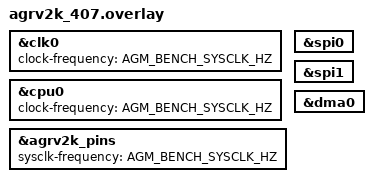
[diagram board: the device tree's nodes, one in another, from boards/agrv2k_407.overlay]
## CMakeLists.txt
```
# SPDX-License-Identifier: Apache-2.0
cmake_minimum_required(VERSION 3.20.0)
find_package(Zephyr REQUIRED HINTS $ENV{ZEPHYR_BASE})
project(fcb_reload)
target_sources(app PRIVATE src/main.c src/spi_id.c)
```

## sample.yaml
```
# SPDX-License-Identifier: Apache-2.0
sample:
  name: fcb_reload
  description: |
    Probe which bitstream is live after a FLASH-side reload: print the FCB
    STAT and a SPI0 RDID so the dev board can show that the fabric content
    follows FLASH while the firmware stays byte-identical. Reload =
    flash_logic.sh + reboot; there is no runtime hot-swap, because on
    AgRV2K the CPU's clock tree comes out of the fabric (see README.md).
    Bench-verified: pending (2026-09-14 board recovery still needed).
tests:
  sample.fcb_reload.agm_agrv2k_407:
    build_only: true
    platform_allow:
      - agrv2k_407
    integration_platforms:
      - agrv2k_407
    tags:
      - ci_build
      - hal_ag32
```

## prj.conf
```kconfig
# SPDX-License-Identifier: Apache-2.0
CONFIG_SERIAL=y
CONFIG_UART_CONSOLE=y
CONFIG_PRINTK=y
CONFIG_STDOUT_CONSOLE=y
CONFIG_XIP=y

# The probe reads the SPI NOR's RDID to tell which bitstream is live, so
# this is the same SPI/DMA set as spi_flash_id. No CONFIG_REBOOT: the
# sample never reboots itself — reloading means flash_logic.sh + reboot.
CONFIG_SPI=y
CONFIG_DMA=y
```

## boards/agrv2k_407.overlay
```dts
/* SPDX-License-Identifier: Apache-2.0 */
/*
 * fcb_reload — 100 MHz SYSCLK overlay.
 *
 * The SPI bitstreams at $HOME/spi_full_bitstream/ and
 * $HOME/spi_full_bitstream_without_flash/ are 100 MHz bitstreams
 * (vendor VE declares SYSCLK 100 / BUSCLK 100 / HSECLK 8). The default
 * agrv2k_407 dts assumes the 200 MHz vendor example_board.bin — running
 * fcb_reload against a 100 MHz bitstream at the default 200 MHz means
 * UART 115200 baud is wrong and the kernel tick drifts.
 *
 * Per the port record (peripherals) (clock tree note): cpu0 ::
 * clock-frequency must stay a literal — sys_clock ticks are computed
 * from it as an integer. &sys clock-frequency follows the same path
 * via DT_PROP. flash-max-frequency = BUSCLK.
 *
 * Use this overlay only for the fcb_reload sample (and any dev board that
 * intentionally targets a 100 MHz bitstream). The hello / IWDG /
 * SPI quad / pm_gate_audit dev boards keep the default 200 MHz.
 *
 * One number, four consumers (firmware clk0/cpu0 + the pin map the
 * bitstream is rendered from): generate_board_ve.py fails if the pin map
 * and &clk0/&cpu0 disagree, which is how this overlay's original
 * 100-vs-200 split was caught (2026-09-15).
 */
#define AGM_BENCH_SYSCLK_HZ 100000000

&clk0 {
	clock-frequency = <AGM_BENCH_SYSCLK_HZ>;
};

&cpu0 {
	clock-frequency = <AGM_BENCH_SYSCLK_HZ>;
};

&agrv2k_pins {
	sysclk-frequency = <AGM_BENCH_SYSCLK_HZ>;
};

&spi0 {
	status = "okay";
};

/* Which controller reaches the flash is a bitstream property, so probe
 * both: <build_dir>/zephyr/board.bin routes SPI1 to the flash, while the
 * spi_full_bitstream family puts it behind SPI0's fabric patch. Reading
 * the RDID off the wrong one returns zeros, not a failure. */
&spi1 {
	status = "okay";
};

&dma0 {
	status = "okay";
};
```

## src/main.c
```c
/*
 * Copyright (c) 2026 AgRV Contributors
 * SPDX-License-Identifier: Apache-2.0
 *
 * fcb_reload — reload the bitstream *from FLASH*, the boot way, on agrv2k_407.
 *
 * The reload this sample demonstrates is: change the image at
 * FCB_BITSTREAM_ADDR, reboot, watch the fabric change. It is the *boot* path
 * on purpose — on AgRV2K the CPU's clock tree is produced by the fabric
 * itself, so a DEACTIVATE/AutoConfig/ACTIVATE sequence run as-is freezes the
 * core mid-instruction, takes the console with it and leaves the SWD AP
 * stalled. The 2026-09-14 dev board ended exactly there; see the block comment in
 * soc/agm/agrv2k/fcb.c and the port record (peripherals) 3.8.1.
 *
 * The runtime version now exists: samples/fcb_hotswap parks the CPU on HSI
 * (a clock the fabric does not own) for the window, validates the target
 * image first, and re-hands the clock tree + pin routes to the new fabric.
 * Measured both directions 2026-09-14 — the port record (peripherals) 3.8.3.
 *
 * So this sample is a probe: it prints the reset reason, the FCB STAT and a
 * SPI NOR RDID, which is all the dev board needs to tell which bitstream is live.
 *
 * Bench (both bitstreams are 100 MHz, hence the 100 MHz overlay):
 *
 *   bash tools/flash_logic.sh $HOME/spi_full_bitstream/example_board.bin
 *   bash tools/test_uart_capture.sh -n -t 8 <this sample's zephyr.bin>
 *     -> FCB boot: STAT=0x... (ACTIVE), RDID = C8 40 16 (flash on SPI0)
 *
 *   bash tools/flash_logic.sh \
 *        $HOME/spi_full_bitstream_without_flash/example_board.bin
 *   bash tools/test_uart_capture.sh -n -t 8        # same firmware!
 *     -> FCB boot: STAT=0x... (ACTIVE), RDID = FF FF FF (SPI0 goes nowhere)
 *
 * Pass: both boots report FCB ACTIVE, and the RDID follows the *bitstream*
 * while the firmware stays byte-identical. That is the whole point — the
 * fabric content follows FLASH, and the CPU came up normally on both.
 *
 * Commands: s = re-probe, q = halt here (SWD attach point), h = help.
 */

#include <zephyr/kernel.h>
#include <zephyr/sys/printk.h>
#include <zephyr/sys/sys_io.h>
#include <zephyr/drivers/uart.h>
#include <zephyr/device.h>
#include <zephyr/devicetree.h>

#include <stdint.h>

/* soc/agm/agrv2k/fcb.c — the same entry point soc.c uses at boot. */
extern void agrv2k_fcb_log_status(const char *tag);

/* Trimmed copy of samples/spi_flash_id — see src/spi_id.c. */
extern int fcb_reload_rdid(uint8_t out[3]);

/* SYS controller reset-flag register (RST_CNTL, bit 24 = write-1-to-clear). */
#define SYS_RST_CNTL   0x03000004UL
#define SYS_RST_REMOVE BIT(24)

/*
 * Which part answers depends on the board and on which controller the
 * bitstream routes to it, so the probe reports what it reads instead of
 * asserting one part number:
 *   C8 40 16  GD25Qxx (the flash this dev board normally has on SPI0)
 *   68 40 15  W25Q16 (what samples/spi_flash_id sees on the other bitstream)
 *   00 00 00  nothing answering with the line held low (measured on
 *             spi_full_bitstream_without_flash)
 *   FF FF FF  nothing answering, line floating high
 */
static const char *rdid_part(uint8_t a, uint8_t b, uint8_t c)
{
	if (a == 0xC8U && b == 0x40U && c == 0x16U) {
		return "GD25Qxx";
	}
	if (a == 0x68U && b == 0x40U && c == 0x15U) {
		return "W25Q16";
	}
	if (a == 0x00U && b == 0x00U && c == 0x00U) {
		return "nothing answering (MISO held low)";
	}
	if (a == 0xFFU && b == 0xFFU && c == 0xFFU) {
		return "nothing answering (MISO floating high)";
	}
	return "unexpected";
}

static const struct device *console_dev(void)
{
	return DEVICE_DT_GET(DT_CHOSEN(zephyr_console));
}

static void probe(const char *tag)
{
	uint8_t rdid[3] = { 0U, 0U, 0U };
	int rc = fcb_reload_rdid(rdid);

	/* FCB STAT first: it is the one line that says whether the
	 * boot-time fabric load succeeded.
	 */
	agrv2k_fcb_log_status(tag);

	if (rc == 0) {
		printk("fcb_reload [%s]: RDID = %02x %02x %02x (%s)\n",
		       tag, rdid[0], rdid[1], rdid[2],
		       rdid_part(rdid[0], rdid[1], rdid[2]));
	} else {
		/* Legitimate when the bitstream routes SPI0 nowhere: the TX
		 * side still completes, the RX side reports -EIO.
		 */
		printk("fcb_reload [%s]: RDID read failed (%d) — SPI0 not driven\n",
		       tag, rc);
	}
}

static void cmd_help(void)
{
	printk("fcb_reload commands:\n");
	printk("  s  re-probe: FCB STAT + SPI0 RDID\n");
	printk("  q  halt here — SWD attach point\n");
	printk("  h  this menu\n");
	printk("note: reloading a bitstream = flash_logic.sh + reboot;\n");
	printk("      there is no runtime hot-swap (see README.md)\n");
}

static void handle_cmd(char c)
{
	switch (c) {
	case 's':
	case 'S':
		probe("s");
		break;
	case 'q':
	case 'Q':
		printk("fcb_reload: halted — SWD may attach\n");
		for (;;) {
			k_msleep(1000);
		}
	case 'h':
	case 'H':
	case '?':
		cmd_help();
		break;
	case '\r':
	case '\n':
		break;
	default:
		printk("? '%c' (press h for help)\n", c);
		break;
	}
}

int main(void)
{
	const struct device *uart = console_dev();
	uint32_t rst;
	char c;

	if (!device_is_ready(uart)) {
		for (;;) {
			k_msleep(1000);
		}
	}

	rst = sys_read32(SYS_RST_CNTL);
	printk("\nfcb_reload: bitstream-from-FLASH probe (boot path)\n");
	printk("fcb_reload: RST_CNTL=0x%08x\n", rst);
	/* Clear the sticky reset flags so the next run starts clean. */
	sys_write32(rst | SYS_RST_REMOVE, SYS_RST_CNTL);

	probe("boot");
	cmd_help();
	printk("fcb_reload> ");

	for (;;) {
		if (uart_poll_in(uart, &c) == 0) {
			handle_cmd(c);
			printk("fcb_reload> ");
		}
		k_msleep(10);
	}
}
```

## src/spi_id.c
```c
/*
 * Copyright (c) 2026 AgRV Contributors
 * SPDX-License-Identifier: Apache-2.0
 *
 * RDID probe for fcb_reload. Same pattern as samples/spi_flash_id
 * but trimmed to a single command (0x9F, 3-byte response) so the
 * sample compiles without pulling the whole spi_flash_id surface.
 *
 * The shape of the call matches the AgRV2K SPI phase engine's
 * constraint: a transfer starts with TX, RX is the last segment,
 * and the driver's TX-then-RX cycle hides the command bytes as
 * 0xFF in the first RX slot.
 */

#include <errno.h>
#include <stdint.h>

#include <zephyr/device.h>
#include <zephyr/devicetree.h>
#include <zephyr/drivers/spi.h>
#include <zephyr/sys/printk.h>

#if !DT_HAS_COMPAT_STATUS_OKAY(agm_agrv2k_spi)
#error "fcb_reload: need agm,agrv2k-spi enabled in the build"
#endif

#define FCB_RELOAD_SPI_ENTRY(node) DEVICE_DT_GET(node),

static const struct device *const spi_controllers[] = {
	DT_FOREACH_STATUS_OKAY(agm_agrv2k_spi, FCB_RELOAD_SPI_ENTRY)
};

#define SPI_FLASH_CMD_RDID  0x9FU

static const struct spi_config spi_cfg = {
	.frequency = 1000000U, /* 1 MHz — conservative for an unknown bitstream */
	.operation = SPI_OP_MODE_CONTROLLER | SPI_WORD_SET(8) | SPI_TRANSFER_MSB,
	.slave = 0,
	.cs = { .cs_is_gpio = false },
};

static int rdid_once(const struct device *spi, uint8_t out[3])
{
	uint8_t cmd = SPI_FLASH_CMD_RDID;
	uint8_t echo;
	uint8_t rx[3] = { 0 };
	struct spi_buf tx_buf = { .buf = &cmd, .len = 1U };
	struct spi_buf rx_bufs[2] = {
		{ .buf = &echo, .len = 1U },
		{ .buf = rx, .len = 3U },
	};
	const struct spi_buf_set tx_set = { .buffers = &tx_buf, .count = 1U };
	const struct spi_buf_set rx_set = { .buffers = rx_bufs, .count = 2U };

	int ret = spi_transceive(spi, &spi_cfg, &tx_set, &rx_set);

	if (ret < 0) {
		return ret;
	}
	out[0] = rx[0];
	out[1] = rx[1];
	out[2] = rx[2];
	return 0;
}

/*
 * Which controller reaches the flash is a bitstream property, so probe every
 * enabled one and report the first that actually answers (a controller whose
 * MISO never arrives reads back all-0x00, and one that is wired to nothing
 * reads all-0xff -- neither is a failure worth stopping on). The first blank
 * result is kept so a bitstream that routes SPI nowhere still prints
 * something meaningful.
 */
int fcb_reload_rdid(uint8_t out[3])
{
	bool have_blank = false;
	uint8_t blank[3] = { 0 };

	for (size_t i = 0; i < ARRAY_SIZE(spi_controllers); i++) {
		const struct device *spi = spi_controllers[i];
		uint8_t r[3] = { 0 };

		if (!device_is_ready(spi)) {
			continue;
		}
		if (rdid_once(spi, r) < 0) {
			printk("fcb_reload: %s RDID read failed\n", spi->name);
			continue;
		}

		printk("fcb_reload: %s RDID = %02x %02x %02x\n",
		       spi->name, r[0], r[1], r[2]);

		if (r[0] != 0x00U || r[1] != 0x00U || r[2] != 0x00U) {
			if (r[0] != 0xFFU || r[1] != 0xFFU || r[2] != 0xFFU) {
				out[0] = r[0];
				out[1] = r[1];
				out[2] = r[2];
				return 0;
			}
		}

		if (!have_blank) {
			blank[0] = r[0];
			blank[1] = r[1];
			blank[2] = r[2];
			have_blank = true;
		}
	}

	if (!have_blank) {
		return -ENODEV;
	}
	out[0] = blank[0];
	out[1] = blank[1];
	out[2] = blank[2];
	return 0;
}
```
